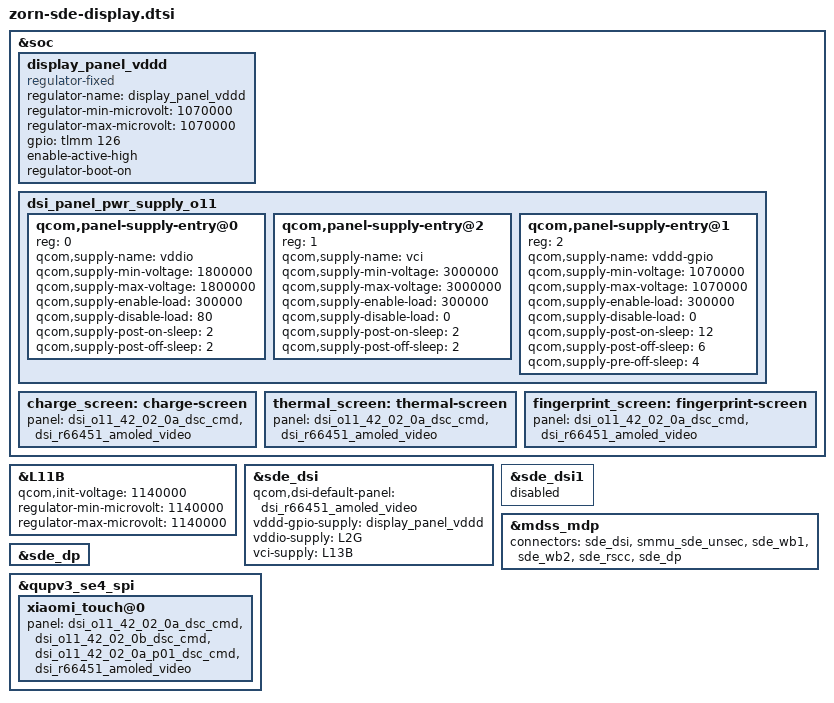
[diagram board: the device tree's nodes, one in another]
#include "pineapple-sde-display.dtsi"
#include "dsi-panel-o11-42-02-0a-dsc-cmd.dtsi"
#include "dsi-panel-o11-42-02-0b-dsc-cmd.dtsi"
#include "dsi-panel-o11-42-02-0a-p01-dsc-cmd.dtsi"
#include "dsi-panel-r66451-dsc-fhd-plus-video.dtsi"


&soc {
	display_panel_vddd: display_panel_vddd {
		compatible = "regulator-fixed";
		regulator-name = "display_panel_vddd";
		regulator-min-microvolt = <1070000>;
		regulator-max-microvolt = <1070000>;
		gpio = <&tlmm 126 0>;
		enable-active-high;
		regulator-boot-on;
    };

	dsi_panel_pwr_supply_o11: dsi_panel_pwr_supply_o11 {
		qcom,panel-supply-entry@0 {
			reg = <0>;
			qcom,supply-name = "vddio";
			qcom,supply-min-voltage = <1800000>;
			qcom,supply-max-voltage = <1800000>;
			qcom,supply-enable-load = <300000>;
			qcom,supply-disable-load = <80>;
			qcom,supply-post-on-sleep = <2>;
			qcom,supply-post-off-sleep = <2>;
		};
		qcom,panel-supply-entry@2 {
			reg = <1>;
			qcom,supply-name = "vci";
			qcom,supply-min-voltage = <3000000>;
			qcom,supply-max-voltage = <3000000>;
			qcom,supply-enable-load = <300000>;
			qcom,supply-disable-load = <0>;
			qcom,supply-post-on-sleep = <2>;
			qcom,supply-post-off-sleep = <2>;
		};
		qcom,panel-supply-entry@1 {
			reg = <2>;
			qcom,supply-name = "vddd-gpio";
			qcom,supply-min-voltage = <1070000>;
			qcom,supply-max-voltage = <1070000>;
			qcom,supply-enable-load = <300000>;
			qcom,supply-disable-load = <0>;
			qcom,supply-post-on-sleep = <12>;
			qcom,supply-post-off-sleep = <6>;
			qcom,supply-pre-off-sleep = <4>;
		};
	};
};

&L11B {
	qcom,init-voltage = <1140000>;
	regulator-min-microvolt = <1140000>;
	regulator-max-microvolt = <1140000>;
};

&sde_dsi {
	qcom,dsi-default-panel = <&dsi_r66451_amoled_video>;
	vddd-gpio-supply = <&display_panel_vddd>;
	vddio-supply = <&L2G>;
	vci-supply = <&L13B>;
};

&sde_dsi1 {
	status = "disabled";
};

&mdss_mdp {
	connectors = <&sde_dsi &smmu_sde_unsec &sde_wb1 &sde_wb2 &sde_rscc &sde_dp>;
};

&sde_dp {
	status = "ok";
};

&qupv3_se4_spi {
	xiaomi_touch@0 {
		panel = <&dsi_o11_42_02_0a_dsc_cmd
			&dsi_o11_42_02_0b_dsc_cmd
			&dsi_o11_42_02_0a_p01_dsc_cmd
			&dsi_r66451_amoled_video>;
	};
};

&soc {
	charge_screen: charge-screen {
		panel  = <&dsi_o11_42_02_0a_dsc_cmd
			&dsi_r66451_amoled_video>;
	};
};

&soc {
	thermal_screen: thermal-screen {
		panel = <&dsi_o11_42_02_0a_dsc_cmd
			&dsi_r66451_amoled_video>;
	};
	fingerprint_screen: fingerprint-screen {
		panel = <&dsi_o11_42_02_0a_dsc_cmd
			&dsi_r66451_amoled_video>;
	};
};
